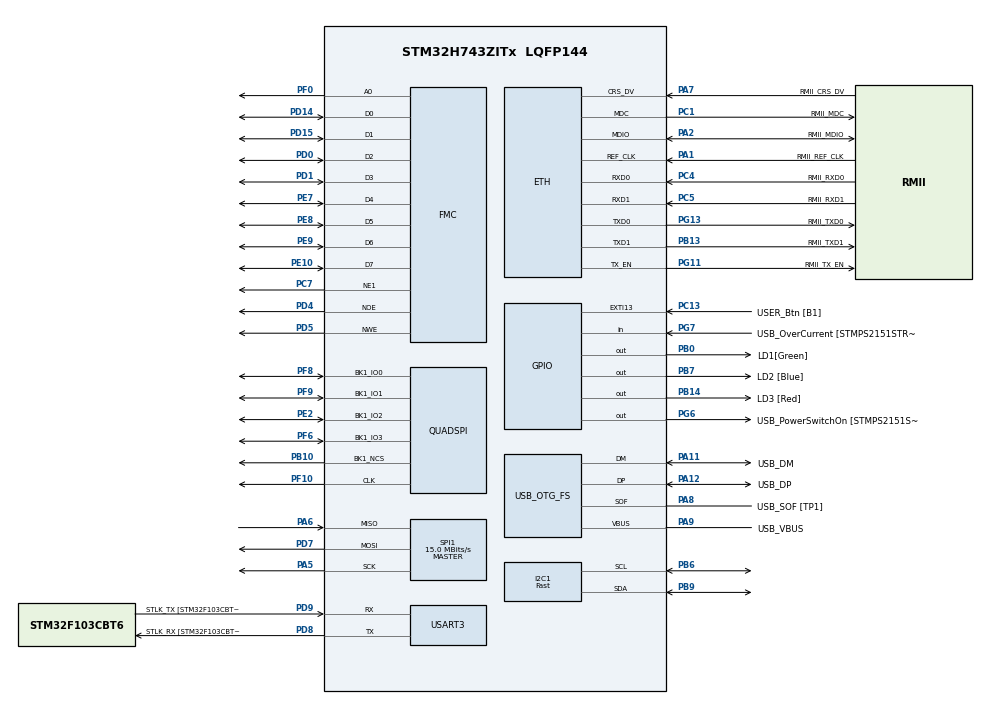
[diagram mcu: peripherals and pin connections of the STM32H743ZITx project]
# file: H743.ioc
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CORTEX_M7.AccessPermission-Cortex_Memory_Protection_Unit_Region0_Settings=MPU_REGION_FULL_ACCESS
CORTEX_M7.AccessPermission-Cortex_Memory_Protection_Unit_Region1_Settings=MPU_REGION_FULL_ACCESS
CORTEX_M7.BaseAddress-Cortex_Memory_Protection_Unit_Region0_Settings=0x30040000
CORTEX_M7.BaseAddress-Cortex_Memory_Protection_Unit_Region1_Settings=0x30044000
CORTEX_M7.CPU_DCache=Enabled
CORTEX_M7.CPU_ICache=Enabled
CORTEX_M7.Enable-Cortex_Memory_Protection_Unit_Region0_Settings=MPU_REGION_ENABLE
CORTEX_M7.Enable-Cortex_Memory_Protection_Unit_Region1_Settings=MPU_REGION_ENABLE
CORTEX_M7.IsBufferable-Cortex_Memory_Protection_Unit_Region0_Settings=MPU_ACCESS_BUFFERABLE
CORTEX_M7.IsShareable-Cortex_Memory_Protection_Unit_Region1_Settings=MPU_ACCESS_SHAREABLE
CORTEX_M7.MPU_Control=MPU_PRIVILEGED_DEFAULT
CORTEX_M7.Size-Cortex_Memory_Protection_Unit_Region0_Settings=MPU_REGION_SIZE_256B
CORTEX_M7.Size-Cortex_Memory_Protection_Unit_Region1_Settings=MPU_REGION_SIZE_16KB
CORTEX_M7.TypeExtField-Cortex_Memory_Protection_Unit_Region1_Settings=MPU_TEX_LEVEL1
Dma.Request0=SPI1_TX
Dma.SPI1_TX.0.Direction=DMA_MEMORY_TO_PERIPH
Dma.SPI1_TX.0.EventEnable=DISABLE
Dma.SPI1_TX.0.FIFOMode=DMA_FIFOMODE_DISABLE
Dma.SPI1_TX.0.Instance=DMA1_Stream0
Dma.SPI1_TX.0.MemDataAlignment=DMA_MDATAALIGN_BYTE
Dma.SPI1_TX.0.MemInc=DMA_MINC_ENABLE
Dma.SPI1_TX.0.Mode=DMA_NORMAL
Dma.SPI1_TX.0.PeriphDataAlignment=DMA_PDATAALIGN_BYTE
Dma.SPI1_TX.0.PeriphInc=DMA_PINC_DISABLE
Dma.SPI1_TX.0.Polarity=HAL_DMAMUX_REQ_GEN_RISING
Dma.SPI1_TX.0.Priority=DMA_PRIORITY_LOW
Dma.SPI1_TX.0.RequestNumber=1
Dma.SPI1_TX.0.SignalID=NONE
Dma.SPI1_TX.0.SyncEnable=DISABLE
Dma.SPI1_TX.0.SyncPolarity=HAL_DMAMUX_SYNC_NO_EVENT
Dma.SPI1_TX.0.SyncRequestNumber=1
Dma.SPI1_TX.0.SyncSignalID=NONE
ETH.MediaInterface=HAL_ETH_RMII_MODE
FATFS._FS_EXFAT=1
FATFS._MAX_SS=4096
FATFS._USE_LFN=3
FMC.AddressSetupTime1=8
FMC.BusTurnAroundDuration1=8
FMC.DataSetupTime1=254
FREERTOS.INCLUDE_xTaskGetCurrentTaskHandle=1
FREERTOS.Tasks01=defaultTask,24,512,StartDefaultTask,Default,NULL,Dynamic,NULL,NULL;myTaskMain,8,1024,StartTaskMain,Default,NULL,Dynamic,NULL,NULL;myTaskGUI,8,4096,StartTaskGUI,Default,NULL,Dynamic,NULL,NULL
FREERTOS.configCHECK_FOR_STACK_OVERFLOW=2
FREERTOS.configENABLE_FPU=1
FREERTOS.configGENERATE_RUN_TIME_STATS=1
FREERTOS.configMINIMAL_STACK_SIZE=512
FREERTOS.configRECORD_STACK_HIGH_ADDRESS=1
FREERTOS.configTOTAL_HEAP_SIZE=72000
FREERTOS.configUSE_STATS_FORMATTING_FUNCTIONS=1
FREERTOS.configUSE_TICKLESS_IDLE=0
I2C1.I2C_Speed_Mode=I2C_Fast
I2C1.Timing=0x00B03FDB
LWIP.BSP.number=1
LWIP.CHECKSUM_CHECK_ICMP=0
LWIP.CHECKSUM_GEN_ICMP=0
LWIP.DEFAULT_THREAD_STACKSIZE=3072
LWIP.GATEWAY_ADDRESS=010.055.001.001
LWIP.IP_ADDRESS=010.055.001.001
LWIP.LWIP_BROADCAST_PING=1
LWIP.LWIP_DHCP=0
LWIP.LWIP_HTTPD=1
LWIP.LWIP_HTTPD_CGI=1
LWIP.LWIP_HTTPD_CGI_SSI=0
LWIP.LWIP_HTTPD_DYNAMIC_HEADERS=1
LWIP.LWIP_HTTPD_FS_ASYNC_READ=1
LWIP.LWIP_HTTPD_MAX_TAG_NAME_LEN=16
LWIP.LWIP_HTTPD_SSI=1
LWIP.LWIP_HTTPD_SUPPORT_POST=1
LWIP.LWIP_MPU_COMPATIBLE=0
LWIP.LWIP_MULTICAST_PING=1
LWIP.LWIP_NETCONN_FULLDUPLEX=1
LWIP.LWIP_NETIF_STATUS_CALLBACK=1
LWIP.LWIP_SMTP=0
LWIP.LWIP_SNMP=1
LWIP.LWIP_SNTP=1
LWIP.LWIP_SO_RCVBUF=1
LWIP.LWIP_SO_RCVTIMEO=1
LWIP.LWIP_TCPIP_TIMEOUT=1
LWIP.LWIP_TCP_KEEPALIVE=1
LWIP.MEMP_NUM_NETBUF=10
LWIP.MEMP_NUM_TCP_PCB_LISTEN=10
LWIP.MEMP_NUM_TCP_SEG=32
LWIP.MEM_SIZE=4096
LWIP.NETMASK_ADDRESS=255.255.255.000
LWIP.SLIPIF_THREAD_STACKSIZE=3072
LWIP.SNMP_STACK_SIZE=3072
LWIP.SNMP_USE_NETCONN=1
LWIP.SNMP_USE_RAW=0
LWIP.TCPIP_THREAD_PRIO=40
LWIP.TCPIP_THREAD_STACKSIZE=3072
LWIP.TCP_DEFAULT_LISTEN_BACKLOG=4
LWIP.TCP_LISTEN_BACKLOG=1
LWIP.TCP_MSS=1460
LWIP.Version=v2.1.2_Cube
LWIP0.BSP.STBoard=false
LWIP0.BSP.api=BSP_COMPONENT_DRIVER
LWIP0.BSP.component=LAN8742
LWIP0.BSP.i2caddr=0
LWIP0.BSP.instance=LAN8742
LWIP0.BSP.name=Driver_PHY
LWIP0.BSP.solution=LAN8742
Mcu.Family=STM32H7
Mcu.Name=STM32H743ZITx
Mcu.Package=LQFP144
NVIC.DMA1_Stream0_IRQn=true\:5\:0\:false\:false\:true\:true\:false\:true
NVIC.ETH_IRQn=true\:5\:0\:false\:false\:true\:true\:true\:true
NVIC.OTG_FS_IRQn=true\:5\:0\:false\:false\:true\:true\:false\:true
NVIC.PriorityGroup=NVIC_PRIORITYGROUP_4
NVIC.SPI1_IRQn=true\:5\:0\:false\:false\:true\:true\:false\:true
NVIC.TIM6_DAC_IRQn=true\:0\:0\:false\:false\:true\:false\:false\:true
NVIC.TimeBase=TIM6_DAC_IRQn
NVIC.TimeBaseIP=TIM6
PA1.GPIO_Label=RMII_REF_CLK
PA1.Mode=RMII
PA1.Signal=ETH_REF_CLK
PA10.GPIO_Label=USB_ID
PA10.Signal=USB_OTG_FS_ID
PA11.GPIO_Label=USB_DM
PA11.Mode=Device_Only
PA11.Signal=USB_OTG_FS_DM
PA12.GPIO_Label=USB_DP
PA12.Mode=Device_Only
PA12.Signal=USB_OTG_FS_DP
PA13\ (JTMS/SWDIO).Mode=Serial_Wire
PA13\ (JTMS/SWDIO).Signal=DEBUG_JTMS-SWDIO
PA14\ (JTCK/SWCLK).Mode=Serial_Wire
PA14\ (JTCK/SWCLK).Signal=DEBUG_JTCK-SWCLK
PA2.GPIO_Label=RMII_MDIO
PA2.Mode=RMII
PA2.Signal=ETH_MDIO
PA5.Mode=Full_Duplex_Master
PA5.Signal=SPI1_SCK
PA6.Mode=Full_Duplex_Master
PA6.Signal=SPI1_MISO
PA7.GPIO_Label=RMII_CRS_DV
PA7.Mode=RMII
PA7.Signal=ETH_CRS_DV
PA8.GPIO_Label=USB_SOF [TP1]
PA8.Mode=Activate_SOF_FS
PA8.Signal=USB_OTG_FS_SOF
PA9.GPIO_Label=USB_VBUS
PA9.Mode=Activate_VBUS
PA9.Signal=USB_OTG_FS_VBUS
PB0.GPIO_Label=LD1[Green]
PB0.Signal=GPIO_Output
PB10.Mode=Single Bank 1
PB10.Signal=QUADSPI_BK1_NCS
PB13.GPIO_Label=RMII_TXD1
PB13.Mode=RMII
PB13.Signal=ETH_TXD1
PB14.GPIO_Label=LD3 [Red]
PB14.Signal=GPIO_Output
PB6.Mode=I2C
PB6.Signal=I2C1_SCL
PB7.GPIO_Label=LD2 [Blue]
PB7.Signal=GPIO_Output
PB9.Mode=I2C
PB9.Signal=I2C1_SDA
PC1.GPIO_Label=RMII_MDC
PC1.Mode=RMII
PC1.Signal=ETH_MDC
PC13.GPIO_Label=USER_Btn [B1]
PC13.Signal=GPXTI13
PC14-OSC32_IN\ (OSC32_IN).Mode=LSE-External-Oscillator
PC14-OSC32_IN\ (OSC32_IN).Signal=RCC_OSC32_IN
PC15-OSC32_OUT\ (OSC32_OUT).Mode=LSE-External-Oscillator
PC15-OSC32_OUT\ (OSC32_OUT).Signal=RCC_OSC32_OUT
PC4.GPIO_Label=RMII_RXD0
PC4.Mode=RMII
PC4.Signal=ETH_RXD0
PC5.GPIO_Label=RMII_RXD1
PC5.Mode=RMII
PC5.Signal=ETH_RXD1
PC7.Mode=NorPsramChipSelect1_1
PC7.Signal=FMC_NE1
PD0.Signal=FMC_D2_DA2
PD1.Signal=FMC_D3_DA3
PD14.Signal=FMC_D0_DA0
PD15.Signal=FMC_D1_DA1
PD4.Signal=FMC_NOE
PD5.Signal=FMC_NWE
PD7.Mode=Full_Duplex_Master
PD7.Signal=SPI1_MOSI
PD8.GPIO_Label=STLK_RX [STM32F103CBT6_PA3]
PD8.Mode=Asynchronous
PD8.Signal=USART3_TX
PD9.GPIO_Label=STLK_TX [STM32F103CBT6_PA2]
PD9.Mode=Asynchronous
PD9.Signal=USART3_RX
PE10.Signal=FMC_D7_DA7
PE2.Mode=Single Bank 1
PE2.Signal=QUADSPI_BK1_IO2
PE7.Signal=FMC_D4_DA4
PE8.Signal=FMC_D5_DA5
PE9.Signal=FMC_D6_DA6
PF0.Signal=FMC_A0
PF10.Mode=Single Bank 1
PF10.Signal=QUADSPI_CLK
PF6.Mode=Single Bank 1
PF6.Signal=QUADSPI_BK1_IO3
PF8.Mode=Single Bank 1
PF8.Signal=QUADSPI_BK1_IO0
PF9.Mode=Single Bank 1
PF9.Signal=QUADSPI_BK1_IO1
PG11.GPIO_Label=RMII_TX_EN
PG11.Mode=RMII
PG11.Signal=ETH_TX_EN
PG13.GPIO_Label=RMII_TXD0
PG13.Mode=RMII
PG13.Signal=ETH_TXD0
PG6.GPIO_Label=USB_PowerSwitchOn [STMPS2151STR_EN]
PG6.Signal=GPIO_Output
PG7.GPIO_Label=USB_OverCurrent [STMPS2151STR_FAULT]
PG7.Signal=GPIO_Input
PH0-OSC_IN\ (PH0).GPIO_Label=MCO
PH0-OSC_IN\ (PH0).Mode=HSE-External-Clock-Source
PH0-OSC_IN\ (PH0).Signal=RCC_OSC_IN
PH1-OSC_OUT\ (PH1).Signal=RCC_OSC_OUT
ProjectManager.HeapSize=0x400
ProjectManager.StackSize=0x1000
ProjectManager.TargetToolchain=STM32CubeIDE
QUADSPI.ChipSelectHighTime=QSPI_CS_HIGH_TIME_6_CYCLE
QUADSPI.ClockPrescaler=2
QUADSPI.FifoThreshold=4
QUADSPI.FlashSize=25
QUADSPI.SampleShifting=QSPI_SAMPLE_SHIFTING_HALFCYCLE
RCC.48MHZClocksFreq_Value=24000000
RCC.ADCFreq_Value=480000000
RCC.AHBFreq_Value=216000000
RCC.APB1CLKDivider=RCC_HCLK_DIV4
RCC.APB1Freq_Value=120000000
RCC.APB1TimFreq_Value=108000000
RCC.APB2CLKDivider=RCC_HCLK_DIV2
RCC.APB2Freq_Value=120000000
RCC.APB2TimFreq_Value=216000000
RCC.APB3Freq_Value=120000000
RCC.APB4Freq_Value=120000000
RCC.CortexFreq_Value=480000000
RCC.D1PPRE=RCC_APB3_DIV2
RCC.D2PPRE1=RCC_APB1_DIV2
RCC.D2PPRE2=RCC_APB2_DIV2
RCC.D3PPRE=RCC_APB4_DIV2
RCC.DIVM1=1
RCC.DIVM2=1
RCC.DIVM3=1
RCC.DIVN1=120
RCC.DIVN2=120
RCC.DIVN3=120
RCC.DIVQ1=8
RCC.DIVQ3=20
RCC.HCLKFreq_Value=240000000
RCC.HPRE=RCC_HCLK_DIV2
RCC.HSE_VALUE=8000000
RCC.HSI_VALUE=64000000
RCC.PLLM=25
RCC.PLLMUL=RCC_PLL_MUL9
RCC.PLLN=432
RCC.PLLQ=9
RCC.PRESCALERUSB=RCC_USBCLKSOURCE_PLL_DIV1_5
RCC.PWR_Regulator_Voltage_Scale=PWR_REGULATOR_VOLTAGE_SCALE0
RCC.SYSCLKFreq_VALUE=480000000
RCC.SYSCLKSource=RCC_SYSCLKSOURCE_PLLCLK
RCC.SYSCLKSourceVirtual=RCC_SYSCLKSOURCE_PLLCLK
RCC.USBCLockSelection=RCC_USBCLKSOURCE_PLL3
RCC.USBFreq_Value=48000000
RCC.VCOOutputFreq_Value=432000000
SH.FMC_A0.0=FMC_A0,A0_1
SH.FMC_D0_DA0.0=FMC_D0,8b-d1
SH.FMC_D1_DA1.0=FMC_D1,8b-d1
SH.FMC_D2_DA2.0=FMC_D2,8b-d1
SH.FMC_D3_DA3.0=FMC_D3,8b-d1
SH.FMC_D4_DA4.0=FMC_D4,8b-d1
SH.FMC_D5_DA5.0=FMC_D5,8b-d1
SH.FMC_D6_DA6.0=FMC_D6,8b-d1
SH.FMC_D7_DA7.0=FMC_D7,8b-d1
SH.FMC_NOE.0=FMC_NOE,Lcd1
SH.FMC_NWE.0=FMC_NWE,Lcd1
SPI1.BaudRatePrescaler=SPI_BAUDRATEPRESCALER_8
SPI1.CalculateBaudRate=15.0 MBits/s
SPI1.DataSize=SPI_DATASIZE_8BIT
SPI1.Direction=SPI_DIRECTION_2LINES
SPI1.Mode=SPI_MODE_MASTER
SPI1.VirtualType=VM_MASTER
USART3.VirtualMode-Asynchronous=VM_ASYNC
USB_DEVICE.CLASS_NAME_FS=CDC
USB_DEVICE.VirtualMode-CDC_FS=Cdc
USB_DEVICE.VirtualModeFS=Cdc_FS
USB_OTG_FS.VirtualMode=Device_Only
VP_FATFS_VS_Generic.Mode=User_defined
VP_FREERTOS_VS_CMSIS_V2.Mode=CMSIS_V2
VP_LWIP_VS_Enabled.Mode=Enabled
VP_MBEDTLS_VS_MBEDTLS.Mode=Enabled
VP_RNG_VS_RNG.Mode=RNG_Activate
VP_SYS_VS_tim6.Mode=TIM6
VP_USB_DEVICE_VS_USB_DEVICE_CDC_FS.Mode=CDC_FS
board=NUCLEO-H743ZI

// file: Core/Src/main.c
/* USER CODE BEGIN Header */
/**
  ******************************************************************************
  * @file           : main.c
  * @brief          : Main program body
  ******************************************************************************
  * @attention
  *
  * <h2><center>&copy; Copyright (c) 2021 STMicroelectronics.
  * All rights reserved.</center></h2>
  *
  * This software component is licensed by ST under Ultimate Liberty license
  * SLA0044, the "License"; You may not use this file except in compliance with
  * the License. You may obtain a copy of the License at:
  *                             www.st.com/SLA0044
  *
  ******************************************************************************
  */
/* USER CODE END Header */
#include "main.h"
#include "cmsis_os.h"
#include "dma.h"
#include "fatfs.h"
#include "i2c.h"
#include "mbedtls.h"
#include "quadspi.h"
#include "rng.h"
#include "spi.h"
#include "usart.h"
#include "usb_device.h"
#include "gpio.h"
#include "fmc.h"

void SystemClock_Config(void);
static void MPU_Config(void);
void MX_FREERTOS_Init(void);

int main(void)
{

  /* MPU Configuration--------------------------------------------------------*/
  MPU_Config();

  /* Enable I-Cache---------------------------------------------------------*/
  SCB_EnableICache();

  /* Enable D-Cache---------------------------------------------------------*/
  SCB_EnableDCache();

  /* MCU Configuration--------------------------------------------------------*/

  /* Reset of all peripherals, Initializes the Flash interface and the Systick. */
  HAL_Init();

  /* Configure the system clock */
  SystemClock_Config();

  /* Initialize all configured peripherals */
  MX_GPIO_Init();
  MX_DMA_Init();
  MX_USART3_UART_Init();
  MX_FMC_Init();
  MX_QUADSPI_Init();
  MX_MBEDTLS_Init();
  MX_SPI1_Init();
  MX_I2C1_Init();
  MX_RNG_Init();

  /* Init scheduler */
  osKernelInitialize();  /* Call init function for freertos objects (in freertos.c) */
  MX_FREERTOS_Init();
  /* Start scheduler */
  osKernelStart();

  /* We should never get here as control is now taken by the scheduler */
  /* Infinite loop */
  while (1)
  {

  }
}

void SystemClock_Config(void)
{
  RCC_OscInitTypeDef RCC_OscInitStruct = {0};
  RCC_ClkInitTypeDef RCC_ClkInitStruct = {0};

  /** Supply configuration update enable
  */
  HAL_PWREx_ConfigSupply(PWR_LDO_SUPPLY);
  /** Configure the main internal regulator output voltage
  */
  __HAL_PWR_VOLTAGESCALING_CONFIG(PWR_REGULATOR_VOLTAGE_SCALE0);

  while(!__HAL_PWR_GET_FLAG(PWR_FLAG_VOSRDY)) {}
  /** Macro to configure the PLL clock source
  */
  __HAL_RCC_PLL_PLLSOURCE_CONFIG(RCC_PLLSOURCE_HSE);
  /** Initializes the RCC Oscillators according to the specified parameters
  * in the RCC_OscInitTypeDef structure.
  */
  RCC_OscInitStruct.OscillatorType = RCC_OSCILLATORTYPE_HSI48|RCC_OSCILLATORTYPE_HSE;
  RCC_OscInitStruct.HSEState = RCC_HSE_BYPASS;
  RCC_OscInitStruct.HSI48State = RCC_HSI48_ON;
  RCC_OscInitStruct.PLL.PLLState = RCC_PLL_ON;
  RCC_OscInitStruct.PLL.PLLSource = RCC_PLLSOURCE_HSE;
  RCC_OscInitStruct.PLL.PLLM = 1;
  RCC_OscInitStruct.PLL.PLLN = 120;
  RCC_OscInitStruct.PLL.PLLP = 2;
  RCC_OscInitStruct.PLL.PLLQ = 8;
  RCC_OscInitStruct.PLL.PLLR = 2;
  RCC_OscInitStruct.PLL.PLLRGE = RCC_PLL1VCIRANGE_3;
  RCC_OscInitStruct.PLL.PLLVCOSEL = RCC_PLL1VCOWIDE;
  RCC_OscInitStruct.PLL.PLLFRACN = 0;
  if (HAL_RCC_OscConfig(&RCC_OscInitStruct) != HAL_OK)
  {
    Error_Handler();
  }
  /** Initializes the CPU, AHB and APB buses clocks
  */
  RCC_ClkInitStruct.ClockType = RCC_CLOCKTYPE_HCLK|RCC_CLOCKTYPE_SYSCLK
                              |RCC_CLOCKTYPE_PCLK1|RCC_CLOCKTYPE_PCLK2
                              |RCC_CLOCKTYPE_D3PCLK1|RCC_CLOCKTYPE_D1PCLK1;
  RCC_ClkInitStruct.SYSCLKSource = RCC_SYSCLKSOURCE_PLLCLK;
  RCC_ClkInitStruct.SYSCLKDivider = RCC_SYSCLK_DIV1;
  RCC_ClkInitStruct.AHBCLKDivider = RCC_HCLK_DIV2;
  RCC_ClkInitStruct.APB3CLKDivider = RCC_APB3_DIV2;
  RCC_ClkInitStruct.APB1CLKDivider = RCC_APB1_DIV2;
  RCC_ClkInitStruct.APB2CLKDivider = RCC_APB2_DIV2;
  RCC_ClkInitStruct.APB4CLKDivider = RCC_APB4_DIV2;

  if (HAL_RCC_ClockConfig(&RCC_ClkInitStruct, FLASH_LATENCY_4) != HAL_OK)
  {
    Error_Handler();
  }
}

/* MPU Configuration */

void MPU_Config(void)
{
  MPU_Region_InitTypeDef MPU_InitStruct = {0};

  /* Disables the MPU */
  HAL_MPU_Disable();
  /** Initializes and configures the Region and the memory to be protected
  */
  MPU_InitStruct.Enable = MPU_REGION_ENABLE;
  MPU_InitStruct.Number = MPU_REGION_NUMBER0;
  MPU_InitStruct.BaseAddress = 0x30040000;
  MPU_InitStruct.Size = MPU_REGION_SIZE_256B;
  MPU_InitStruct.SubRegionDisable = 0x0;
  MPU_InitStruct.TypeExtField = MPU_TEX_LEVEL0;
  MPU_InitStruct.AccessPermission = MPU_REGION_FULL_ACCESS;
  MPU_InitStruct.DisableExec = MPU_INSTRUCTION_ACCESS_ENABLE;
  MPU_InitStruct.IsShareable = MPU_ACCESS_NOT_SHAREABLE;
  MPU_InitStruct.IsCacheable = MPU_ACCESS_NOT_CACHEABLE;
  MPU_InitStruct.IsBufferable = MPU_ACCESS_BUFFERABLE;

  HAL_MPU_ConfigRegion(&MPU_InitStruct);
  /** Initializes and configures the Region and the memory to be protected
  */
  MPU_InitStruct.Number = MPU_REGION_NUMBER1;
  MPU_InitStruct.BaseAddress = 0x30044000;
  MPU_InitStruct.Size = MPU_REGION_SIZE_16KB;
  MPU_InitStruct.TypeExtField = MPU_TEX_LEVEL1;
  MPU_InitStruct.IsShareable = MPU_ACCESS_SHAREABLE;
  MPU_InitStruct.IsBufferable = MPU_ACCESS_NOT_BUFFERABLE;

  HAL_MPU_ConfigRegion(&MPU_InitStruct);
  /* Enables the MPU */
  HAL_MPU_Enable(MPU_PRIVILEGED_DEFAULT);

}
void HAL_TIM_PeriodElapsedCallback(TIM_HandleTypeDef *htim)
{
  if (htim->Instance == TIM6) {
    HAL_IncTick();
  }
}

void Error_Handler(void)
{
  __disable_irq();
  while (1)
  {
  }
}

/************************ (C) COPYRIGHT STMicroelectronics *****END OF FILE****/

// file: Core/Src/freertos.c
/* USER CODE BEGIN Header */
/**
  ******************************************************************************
  * File Name          : freertos.c
  * Description        : Code for freertos applications
  ******************************************************************************
  * @attention
  *
  * <h2><center>&copy; Copyright (c) 2021 STMicroelectronics.
  * All rights reserved.</center></h2>
  *
  * This software component is licensed by ST under Ultimate Liberty license
  * SLA0044, the "License"; You may not use this file except in compliance with
  * the License. You may obtain a copy of the License at:
  *                             www.st.com/SLA0044
  *
  ******************************************************************************
  */
/* USER CODE END Header */

#include "FreeRTOS.h"
#include "task.h"
#include "main.h"
#include "cmsis_os.h"

/* USER CODE BEGIN Includes */
#include "mbedtls.h"
/* USER CODE END Includes */

/* USER CODE BEGIN PM */
volatile unsigned long ulHighFrequencyTimerTicks;
/* USER CODE END PM */

/* Definitions for defaultTask */
osThreadId_t defaultTaskHandle;
const osThreadAttr_t defaultTask_attributes = {
  .name = "defaultTask",
  .stack_size = 512 * 4,
  .priority = (osPriority_t) osPriorityNormal,
};
/* Definitions for myTaskMain */
osThreadId_t myTaskMainHandle;
const osThreadAttr_t myTaskMain_attributes = {
  .name = "myTaskMain",
  .stack_size = 1024 * 4,
  .priority = (osPriority_t) osPriorityLow,
};
/* Definitions for myTaskGUI */
osThreadId_t myTaskGUIHandle;
const osThreadAttr_t myTaskGUI_attributes = {
  .name = "myTaskGUI",
  .stack_size = 4096 * 4,
  .priority = (osPriority_t) osPriorityLow,
};

void StartDefaultTask(void *argument);
void StartTaskMain(void *argument);
void StartTaskGUI(void *argument);

extern void MX_LWIP_Init(void);
extern void MX_USB_DEVICE_Init(void);
void MX_FREERTOS_Init(void); /* (MISRA C 2004 rule 8.1) */

/* Hook prototypes */
void configureTimerForRunTimeStats(void);
unsigned long getRunTimeCounterValue(void);
void vApplicationStackOverflowHook(xTaskHandle xTask, signed char *pcTaskName);

/* USER CODE BEGIN 1 */
/* Functions needed when configGENERATE_RUN_TIME_STATS is on */
__weak void configureTimerForRunTimeStats(void)
{
	ulHighFrequencyTimerTicks = 0;
}

__weak unsigned long getRunTimeCounterValue(void)
{
	return ulHighFrequencyTimerTicks;
}
/* USER CODE END 1 */

/* USER CODE BEGIN 4 */
void vApplicationStackOverflowHook(xTaskHandle xTask, signed char *pcTaskName)
{
   /* Run time stack overflow checking is performed if
   configCHECK_FOR_STACK_OVERFLOW is defined to 1 or 2. This hook function is
   called if a stack overflow is detected. */
}
/* USER CODE END 4 */

void MX_FREERTOS_Init(void) {

  /* Create the thread(s) */
  /* creation of defaultTask */
  defaultTaskHandle = osThreadNew(StartDefaultTask, NULL, &defaultTask_attributes);

  /* creation of myTaskMain */
  myTaskMainHandle = osThreadNew(StartTaskMain, NULL, &myTaskMain_attributes);

  /* creation of myTaskGUI */
  myTaskGUIHandle = osThreadNew(StartTaskGUI, NULL, &myTaskGUI_attributes);

}

void StartDefaultTask(void *argument)
{
  /* init code for USB_DEVICE */
  MX_USB_DEVICE_Init();
  /* USER CODE BEGIN StartDefaultTask */
  /* Infinite loop */
  for(;;)
  {
	HAL_GPIO_TogglePin(LD3_GPIO_Port, LD3_Pin);
    osDelay(100);
  }
  /* USER CODE END StartDefaultTask */
}

void StartTaskMain(void *argument)
{
  /* USER CODE BEGIN StartTaskMain */

    // Start Ethernet Stack
    MX_LWIP_Init();

  /* Infinite loop */
  for(;;)
  {
	HAL_GPIO_TogglePin(LD1_GPIO_Port, LD1_Pin);
    osDelay(100);
  }
  /* USER CODE END StartTaskMain */
}

void StartTaskGUI(void *argument)
{
  /* USER CODE BEGIN StartTaskGUI */
  /* Infinite loop */
  for(;;)
  {
	HAL_GPIO_TogglePin(LD2_GPIO_Port, LD2_Pin);
    osDelay(100);
  }
  /* USER CODE END StartTaskGUI */
}

/************************ (C) COPYRIGHT STMicroelectronics *****END OF FILE****/
